AUTOSAR XML (schema 00054)
standard types defined: sint16, boolean, uint16
package /AUTOSAR_AISpecification/ApplicationDataTypes
  app type OnOff1: category=BOOLEAN, sw-calibration-access=READ-ONLY, compu {0=Off (0 = Off), 1=On (1 = On)} "On Off 1", range raw 0..1, unit=-  # On Off 1 | Generic On/Off Information
  app type AgSpd2: category=VALUE, sw-calibration-access=READ-ONLY, compu-method=AgSpd2, range phys -5..5 rad/s, sw-intended-resolution=0.0009765625, unit=rad/s  # Angle Speed 2 | Generic data type for angle speed
  app type Spd3: category=VALUE, sw-calibration-access=READ-ONLY, compu {raw=phys*4 for phys 0..125; unit m/s} "Speed 3 | Generic data type for speed", range phys 0..125 m/s, sw-intended-resolution=0.25, unit=m/s  # Speed 3 | Generic data type for speed
package /AUTOSAR_AISpecification/CompuMethods
  compu method AgSpd2: raw=phys*1024 for phys -5..5; unit rad/s  # Angle Speed 2 | Generic data type for angle speed
package /AUTOSAR_AISpecification/PhysicalDimensions
  physical dimension TiNeg1_2: time-exp=-1  # Angular Speed
  physical dimension NoDimension  # Dimensionless
  physical dimension Len1TiNeg1: length-exp=1, time-exp=-1  # Velocity
package /AUTOSAR_AISpecification/PortInterfaces
  sender receiver interface LedCmd1  # Led Command | Command to activate the Antitheft Warning System (ATWS) Light Emitting Diode (LED) on board
    data Cmd: type=OnOff1  # OFF - LED not requested by alarm ON - LED requested by alarm
  sender receiver interface RoadWhlAgSpd1  # Road Wheel Angle Speed 1 | Generic interface for road wheel angle speed
    data RoadWhlAgSpd: type=AgSpd2
  sender receiver interface VehSpd1  # Vehicle Speed 1 | Generic interface for vehicle speed
    data VehSpd: type=Spd3
package /AUTOSAR_AISpecification/Units
  unit RadPerSec: display-name=rad/s, factor-si-to-unit=1.0, physical-dimension=TiNeg1_2  # Radian per Second | SI derived unit of angular velocity
  unit NoUnit: display-name=-, factor-si-to-unit=1.0, physical-dimension=NoDimension  # No Unit | Unit for dimensionless continuous value data types like numbers, factors and coefficients
  unit MtrPerSec: display-name=m/s, factor-si-to-unit=1.0, physical-dimension=Len1TiNeg1  # Meter per Second | SI derived unit of velocity
package /CommunicationClusters
  can cluster CanCluster: baudrate=500000, protocol-name=CAN
    can physical channel CanPhysicalChannel: comm-connectors=VehSpd_CanConnector
      frame CanFrame_EcuVehSpd_RoadWhlAgSpd_Rx: id 0x100, to VehicleSpeed, frame-length=8, can-addressing-mode=STANDARD, can-frame-rx-behavior=CAN-20
        carries pdu ISIPdu_EcuVehSpd_RoadWhlAgSpd_Rx: packing-byte-order=little-endian, start-position=0, update-indication-bit-position=0
        pdu ISIPdu_EcuVehSpd_RoadWhlAgSpd_Rx: length=8, unused-bit-pattern=0
          signal ISig_EcuVehSpd_RoadWhlAgSpd_Rx: start 0, 16 bit, little-endian, system signal SysSig_EcuVehSpd_RoadWhlAgSpd_Rx, base-type=sint16, compu-method=AgSpd2, to VehicleSpeed
package /EcuInstances
  ecu instance VehicleSpeed
    can communication controller VehSpd_CanController: wake-up-by-controller-supported=false, can-controller-attributes=can-controller-configuration={prop-seg=8, sync-jump-width=3, time-seg-1=7, time-seg-2=4}
    can communication connector VehSpd_CanConnector: comm-controller=VehSpd_CanController
    ecu partition EcuPartVehSpd
package /EcuVehicleSpeed
  hw element VehicleSpeed: hw-type=EcuType, hw-category=Ecu
    hw pin group CanBus
package /HwCategorys
  hw category Ecu
  hw category Digital
  hw category SensorActuator
package /HwTypes
  hw type EcuType: hw-category=Ecu
  hw type IoDType: hw-category=Digital
  hw type SensorActuatorType: hw-category=SensorActuator
package /Pkg_ImplementationDataTypes
  impl type OnOff1_Impl: implementation-data-type=boolean
  impl type Spd3_Impl: implementation-data-type=uint16
  impl type AgSpd2_Impl: implementation-data-type=sint16
package /Pkg_MappingSets
  data type mapping set DataTypeMappingSet_LedOnOff: data-type-map{application-data-type=OnOff1, implementation-data-type=OnOff1_Impl}
  data type mapping set DataTypeMappingSet_Spd: data-type-map{application-data-type=Spd3, implementation-data-type=Spd3_Impl}
  data type mapping set DataTypeMappingSet_AgSpd: data-type-map{application-data-type=AgSpd2, implementation-data-type=AgSpd2_Impl}
package /SwComponentTypes
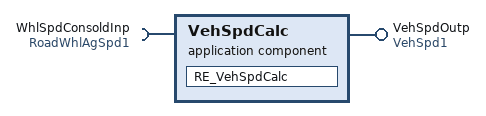
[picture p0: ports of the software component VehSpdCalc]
  application sw component type VehSpdCalc
    require port WhlSpdConsoldInp: nonqueued-receiver-com-spec{data-element=RoadWhlAgSpd, init-value=Default_WhlSpdConsoldInp:0}, required-interface=RoadWhlAgSpd1
    provide port VehSpdOutp: provided-interface=VehSpd1
    behavior VehSpdCalc_IB: data-type-mapping=[DataTypeMappingSet_AgSpd, DataTypeMappingSet_Spd], supports-multiple-instantiation=true
      data received event DRE_WhlSpdConsoldInp: start-on-event=RE_VehSpdCalc, data=WhlSpdConsoldInp.RoadWhlAgSpd
      runnable RE_VehSpdCalc: minimum-start-interval=0.01
        data-receive-point-by-arguments:
          access DRPA_WhlSpdConsoldInp: accessed-variable=WhlSpdConsoldInp.RoadWhlAgSpd
        data-write-access:
          access DWA_VehSpdOutp: accessed-variable=VehSpdOutp.VehSpd
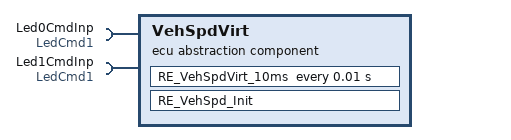
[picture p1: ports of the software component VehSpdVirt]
  ecu abstraction sw component type VehSpdVirt: hardware-element=IoDType
    require port Led0CmdInp: nonqueued-receiver-com-spec{data-element=Cmd, init-value=Default_Led0CmdInp:0}, required-interface=LedCmd1
    require port Led1CmdInp: nonqueued-receiver-com-spec{data-element=Cmd, init-value=Default_Led1CmdInp:0}, required-interface=LedCmd1
    behavior VehSpdVirt_IB: data-type-mapping=DataTypeMappingSet_LedOnOff
      timing event TE_10ms: start-on-event=RE_VehSpdVirt_10ms, period=0.01
      init event IE_WhlSpd_Init: start-on-event=RE_VehSpd_Init
      runnable RE_VehSpdVirt_10ms
        data-read-access:
          access DRA_Led0CmdInp: accessed-variable=Led0CmdInp.Cmd
          access DRA_Led1CmdInp: accessed-variable=Led1CmdInp.Cmd
      runnable RE_VehSpd_Init
  composition sw component type VehicleSpeedComposition
    require port WhlSpdConsoldInp: required-interface=RoadWhlAgSpd1
    component CPT_VehSpdCalc: type=VehSpdCalc
    component CPT_VehSpdActr: type=VehSpdActr
    component CPT_VehSpdVirt: type=VehSpdVirt
    connect CPT_VehSpdActr.Led0CmdOutp -> CPT_VehSpdVirt.Led0CmdInp
    connect CPT_VehSpdActr.Led1CmdOutp -> CPT_VehSpdVirt.Led1CmdInp
    delegate CPT_VehSpdCalc.WhlSpdConsoldInp <-> outer port VehicleSpeedComposition/WhlSpdConsoldInp
    connect CPT_VehSpdCalc.VehSpdOutp -> CPT_VehSpdActr.VehSpdInp
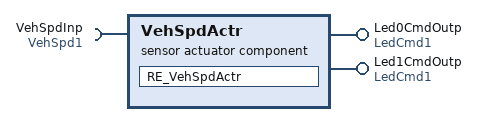
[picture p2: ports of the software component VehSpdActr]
  sensor actuator sw component type VehSpdActr: sensor-actuator=SensorActuatorType
    require port VehSpdInp: nonqueued-receiver-com-spec{data-element=VehSpd, init-value=Default_VehSpdInp:0}, required-interface=VehSpd1
    provide port Led0CmdOutp: provided-interface=LedCmd1
    provide port Led1CmdOutp: provided-interface=LedCmd1
    behavior VehSpdActr_IB: data-type-mapping=[DataTypeMappingSet_Spd, DataTypeMappingSet_LedOnOff], supports-multiple-instantiation=true
      data received event DRE_VehSpdInp: start-on-event=RE_VehSpdActr, data=VehSpdInp.VehSpd
      runnable RE_VehSpdActr: minimum-start-interval=0.01
        data-read-access:
          access DRA_VehSpdInp: accessed-variable=VehSpdInp.VehSpd
        data-write-access:
          access DWA_Led0CmdOutp: accessed-variable=Led0CmdOutp.Cmd
          access DWA_Led1CmdOutp: accessed-variable=Led1CmdOutp.Cmd
package /System
  composition sw component type TopLevelComposition
    require port WhlSpdConsoldInp: required-interface=RoadWhlAgSpd1
    component CPT_VehicleSpeedComposition: type=VehicleSpeedComposition
    delegate CPT_VehicleSpeedComposition.WhlSpdConsoldInp <-> outer port TopLevelComposition/WhlSpdConsoldInp
package /Systems
  system PF_System: category=SYSTEM_EXTRACT, ecu-extract-version=1.0.0, system-version=1.0.0
    system mapping SystemMapping: sender-receiver-to-signal-mapping{data-element=RootSwCompositionPrototype.WhlSpdConsoldInp.RoadWhlAgSpd, system-signal=SysSig_EcuVehSpd_RoadWhlAgSpd_Rx}
      application partition to ecu partition mapping AppPartVehSpd_EcuPartVehSpd: application-partition=AppPartVehSpd, ecu-partition=EcuPartVehSpd
      sw-mappings:
        swc to ecu mapping SWcToECUMapping_VehSpd: component=RootSwCompositionPrototype.CPT_VehicleSpeedComposition, controlled-hw-element=VehicleSpeed, ecu-instance=VehicleSpeed, processing-unit=VehicleSpeed
      swc to application partition mapping SwcToApplicationPartition_AppPartVehSpd: application-partition=AppPartVehSpd, sw-component-prototype=RootSwCompositionPrototype.CPT_VehicleSpeedComposition
    root-software-compositions:
      root sw composition prototype RootSwCompositionPrototype: software-composition=TopLevelComposition
  application partition AppPartVehSpd
